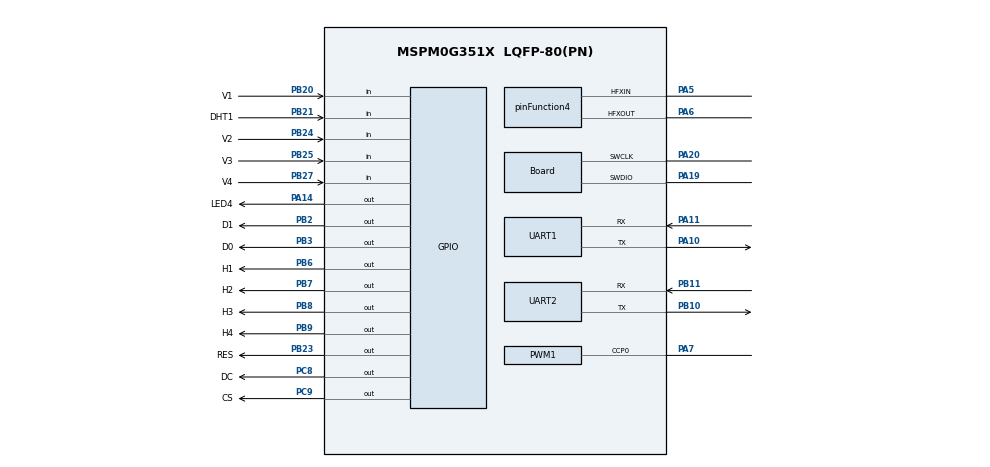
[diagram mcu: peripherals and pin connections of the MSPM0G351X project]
/**
 * @cliArgs --device "MSPM0G351X" --part "Default" --package "LQFP-80(PN)" --product "mspm0_sdk@2.08.00.03"
 * @versions {"tool":"1.27.0+4565"}
 */

/**
 * Import the modules used in this configuration.
 */
const ADC12  = scripting.addModule("/ti/driverlib/ADC12", {}, false);
const ADC121 = ADC12.addInstance();
const DAC12  = scripting.addModule("/ti/driverlib/DAC12");
const DMA    = scripting.addModule("/ti/driverlib/DMA");
const GPIO   = scripting.addModule("/ti/driverlib/GPIO", {}, false);
const GPIO1  = GPIO.addInstance();
const GPIO2  = GPIO.addInstance();
const GPIO3  = GPIO.addInstance();
const GPIO4  = GPIO.addInstance();
const PWM    = scripting.addModule("/ti/driverlib/PWM", {}, false);
const PWM1   = PWM.addInstance();
const SYSCTL = scripting.addModule("/ti/driverlib/SYSCTL");
const TIMER  = scripting.addModule("/ti/driverlib/TIMER", {}, false);
const TIMER1 = TIMER.addInstance();
const TRNG   = scripting.addModule("/ti/driverlib/TRNG");
const UART   = scripting.addModule("/ti/driverlib/UART", {}, false);
const UART1  = UART.addInstance();
const UART2  = UART.addInstance();

/**
 * Write custom configuration values to the imported modules.
 */
const divider2       = system.clockTree["HFCLK4MFPCLKDIV"];
divider2.divideValue = 10;

const divider9       = system.clockTree["UDIV"];
divider9.divideValue = 2;

const gate7  = system.clockTree["MFCLKGATE"];
gate7.enable = true;

const gate8  = system.clockTree["MFPCLKGATE"];
gate8.enable = true;

const multiplier2         = system.clockTree["PLL_QDIV"];
multiplier2.multiplyValue = 4;

const mux4       = system.clockTree["EXHFMUX"];
mux4.inputSelect = "EXHFMUX_XTAL";

const mux8       = system.clockTree["HSCLKMUX"];
mux8.inputSelect = "HSCLKMUX_SYSPLL0";

const mux10       = system.clockTree["MFPCLKMUX"];
mux10.inputSelect = "MFPCLKMUX_HFCLK";

const mux12       = system.clockTree["SYSPLLMUX"];
mux12.inputSelect = "zSYSPLLMUX_HFCLK";

const pinFunction4                        = system.clockTree["HFXT"];
pinFunction4.inputFreq                    = 40;
pinFunction4.enable                       = true;
pinFunction4.HFXTStartup                  = 10;
pinFunction4.peripheral.$assign           = "SYSCTL";
pinFunction4.peripheral.hfxInPin.$assign  = "PA5";
pinFunction4.peripheral.hfxOutPin.$assign = "PA6";

const pinFunction6     = system.clockTree["LFXT"];
pinFunction6.inputFreq = 32.768;

ADC121.$name               = "ADC12_0";
ADC121.repeatMode          = true;
ADC121.sampleTime0         = "0.0125 ms";
ADC121.sampClkDiv          = "DL_ADC12_CLOCK_DIVIDE_8";
ADC121.peripheral.$assign  = "ADC0";
ADC121.adcPin0Config.$name = "ti_driverlib_gpio_GPIOPinGeneric0";

const Board                       = scripting.addModule("/ti/driverlib/Board", {}, false);
Board.peripheral.$assign          = "DEBUGSS";
Board.peripheral.swclkPin.$assign = "PA20";
Board.peripheral.swdioPin.$assign = "PA19";

DAC12.dacOutputPinEn     = true;
DAC12.dacAmplifier       = "ON";
DAC12.OutPinConfig.$name = "ti_driverlib_gpio_GPIOPinGeneric1";

DMA.associatedChannels.create(1);
DMA.associatedChannels[0].$name = "DMA_CH0";

GPIO1.$name                         = "LED";
GPIO1.associatedPins[0].$name       = "LED4";
GPIO1.associatedPins[0].assignedPin = "14";
GPIO1.associatedPins[0].pin.$assign = "PA14";

GPIO2.$name                         = "GPIO_GRP_0";
GPIO2.associatedPins.create(5);
GPIO2.associatedPins[0].$name       = "CS";
GPIO2.associatedPins[0].pin.$assign = "PC9";
GPIO2.associatedPins[1].$name       = "DC";
GPIO2.associatedPins[1].pin.$assign = "PC8";
GPIO2.associatedPins[2].$name       = "D0";
GPIO2.associatedPins[2].pin.$assign = "PB3";
GPIO2.associatedPins[3].$name       = "D1";
GPIO2.associatedPins[3].pin.$assign = "PB2";
GPIO2.associatedPins[4].$name       = "RES";
GPIO2.associatedPins[4].pin.$assign = "PB23";

GPIO3.$name                              = "KEY";
GPIO3.associatedPins.create(8);
GPIO3.associatedPins[0].$name            = "H1";
GPIO3.associatedPins[0].internalResistor = "PULL_UP";
GPIO3.associatedPins[0].pin.$assign      = "PB6";
GPIO3.associatedPins[1].$name            = "H2";
GPIO3.associatedPins[1].internalResistor = "PULL_UP";
GPIO3.associatedPins[1].pin.$assign      = "PB7";
GPIO3.associatedPins[2].$name            = "H3";
GPIO3.associatedPins[2].internalResistor = "PULL_UP";
GPIO3.associatedPins[2].pin.$assign      = "PB8";
GPIO3.associatedPins[3].$name            = "H4";
GPIO3.associatedPins[3].internalResistor = "PULL_UP";
GPIO3.associatedPins[3].pin.$assign      = "PB9";
GPIO3.associatedPins[4].$name            = "V1";
GPIO3.associatedPins[4].direction        = "INPUT";
GPIO3.associatedPins[4].internalResistor = "PULL_DOWN";
GPIO3.associatedPins[4].pin.$assign      = "PB20";
GPIO3.associatedPins[5].$name            = "V2";
GPIO3.associatedPins[5].direction        = "INPUT";
GPIO3.associatedPins[5].internalResistor = "PULL_DOWN";
GPIO3.associatedPins[5].pin.$assign      = "PB24";
GPIO3.associatedPins[6].$name            = "V3";
GPIO3.associatedPins[6].direction        = "INPUT";
GPIO3.associatedPins[6].internalResistor = "PULL_DOWN";
GPIO3.associatedPins[6].pin.$assign      = "PB25";
GPIO3.associatedPins[7].$name            = "V4";
GPIO3.associatedPins[7].direction        = "INPUT";
GPIO3.associatedPins[7].internalResistor = "PULL_DOWN";
GPIO3.associatedPins[7].pin.$assign      = "PB27";

GPIO4.$name                         = "DHT11";
GPIO4.associatedPins[0].$name       = "DHT1";
GPIO4.associatedPins[0].direction   = "INPUT";
GPIO4.associatedPins[0].pin.$assign = "PB21";

PWM1.$name                      = "PWM_0";
PWM1.clockSource                = "MFCLK";
PWM1.clockDivider               = 4;
PWM1.timerCount                 = 20000;
PWM1.pwmMode                    = "EDGE_ALIGN_UP";
PWM1.interrupts                 = ["LOAD_EVENT","OVERFLOW_EVENT"];
PWM1.peripheral.ccp0Pin.$assign = "PA7";
PWM1.PWM_CHANNEL_0.$name        = "ti_driverlib_pwm_PWMTimerCC0";
PWM1.PWM_CHANNEL_0.initVal      = "HIGH";
PWM1.PWM_CHANNEL_0.ccValue      = 500;
PWM1.PWM_CHANNEL_1.$name        = "ti_driverlib_pwm_PWMTimerCC1";
PWM1.ccp0PinConfig.$name        = "ti_driverlib_gpio_GPIOPinGeneric6";
PWM1.ccp1PinConfig.$name        = "ti_driverlib_gpio_GPIOPinGeneric7";

SYSCTL.forceDefaultClkConfig = true;
SYSCTL.clockTreeEn           = true;

TIMER1.$name       = "TIMER_0";
TIMER1.timerMode   = "PERIODIC";
TIMER1.interrupts  = ["ZERO"];
TIMER1.timerClkSrc = "MFCLK";
TIMER1.timerClkDiv = 2;
TIMER1.timerPeriod = "0.03125 ms";

TRNG.clockDivider = "DL_TRNG_CLOCK_DIVIDE_8";

UART1.targetBaudRate                   = 115200;
UART1.$name                            = "UART_0";
UART1.enabledInterrupts                = ["RX","TX"];
UART1.peripheral.$assign               = "UART0";
UART1.peripheral.rxPin.$assign         = "PA11";
UART1.peripheral.txPin.$assign         = "PA10";
UART1.txPinConfig.direction            = scripting.forceWrite("OUTPUT");
UART1.txPinConfig.hideOutputInversion  = scripting.forceWrite(false);
UART1.txPinConfig.onlyInternalResistor = scripting.forceWrite(false);
UART1.txPinConfig.passedPeripheralType = scripting.forceWrite("Digital");
UART1.txPinConfig.$name                = "ti_driverlib_gpio_GPIOPinGeneric2";
UART1.rxPinConfig.hideOutputInversion  = scripting.forceWrite(false);
UART1.rxPinConfig.onlyInternalResistor = scripting.forceWrite(false);
UART1.rxPinConfig.passedPeripheralType = scripting.forceWrite("Digital");
UART1.rxPinConfig.$name                = "ti_driverlib_gpio_GPIOPinGeneric3";

UART2.$name                    = "UART_1";
UART2.peripheral.rxPin.$assign = "PB11";
UART2.peripheral.txPin.$assign = "PB10";
UART2.txPinConfig.$name        = "ti_driverlib_gpio_GPIOPinGeneric4";
UART2.rxPinConfig.$name        = "ti_driverlib_gpio_GPIOPinGeneric5";

const ProjectConfig              = scripting.addModule("/ti/project_config/ProjectConfig", {}, false);
ProjectConfig.migrationCondition = true;

/**
 * Pinmux solution for unlocked pins/peripherals. This ensures that minor changes to the automatic solver in a future
 * version of the tool will not impact the pinmux you originally saw.  These lines can be completely deleted in order to
 * re-solve from scratch.
 */
ADC121.peripheral.adcPin0.$suggestSolution            = "PA27";
DAC12.peripheral.$suggestSolution                     = "DAC0";
DAC12.peripheral.OutPin.$suggestSolution              = "PA15";
DMA.associatedChannels[0].peripheral.$suggestSolution = "DMA_CH0";
PWM1.peripheral.$suggestSolution                      = "TIMG8";
PWM1.peripheral.ccp1Pin.$suggestSolution              = "PA0";
TIMER1.peripheral.$suggestSolution                    = "TIMA0";
UART2.peripheral.$suggestSolution                     = "UART4";
